# CH641 register map
Vendor: WCH Ltd.; File version: 1.1
Registers are 32-bit, read-write, reset 0x0 unless marked. A register's access mark holds for its fields unless they carry their own. Offsets are from the block's base; [hi:lo] are bit positions; {n}, {i} and the like mark numbered series.

## PFIC — Programmable Fast Interrupt Controller
Base 0xE000E000
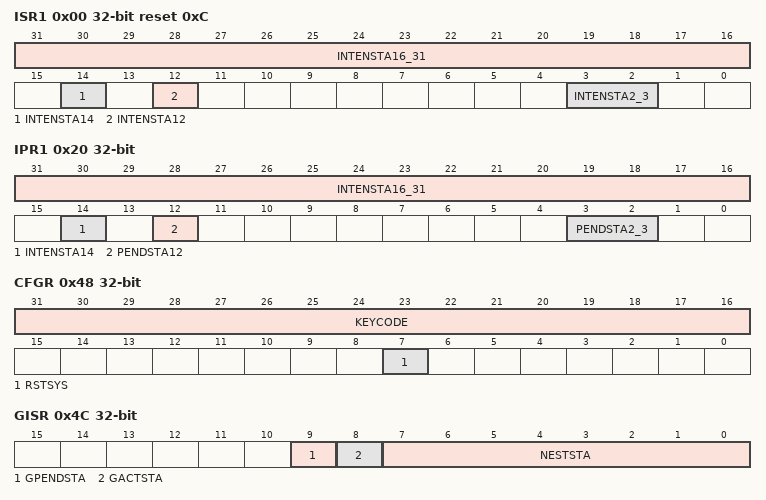
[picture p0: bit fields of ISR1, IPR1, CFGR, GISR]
0x00 ISR1 ro reset 0xC — Interrupt Status Register
  [31:16] INTENSTA16_31 — Interrupt ID Status
  [14] INTENSTA14 — Interrupt ID Status
  [12] INTENSTA12 — Interrupt ID Status
  [3:2] INTENSTA2_3 — Interrupt ID Status
0x04 ISR2 ro — Interrupt Status Register
  [6:0] INTENSTA — Interrupt ID Status
0x20 IPR1 ro — Interrupt Pending Register
  [31:16] INTENSTA16_31 — PENDSTA
  [14] INTENSTA14 — PENDSTA
  [12] PENDSTA12 — PENDSTA
  [3:2] PENDSTA2_3 — PENDSTA
0x24 IPR2 ro — Interrupt Pending Register
  [6:0] PENDSTA32_38 — PENDSTA
0x40 ITHRESDR — Interrupt Priority Register
  [7:0] THRESHOLD
0x48 CFGR wo — Interrupt Config Register
  [31:16] KEYCODE
  [7] RSTSYS — RESET System
0x4C GISR ro — Interrupt Global Register
  [9] GPENDSTA, [8] GACTSTA, [7:0] NESTSTA
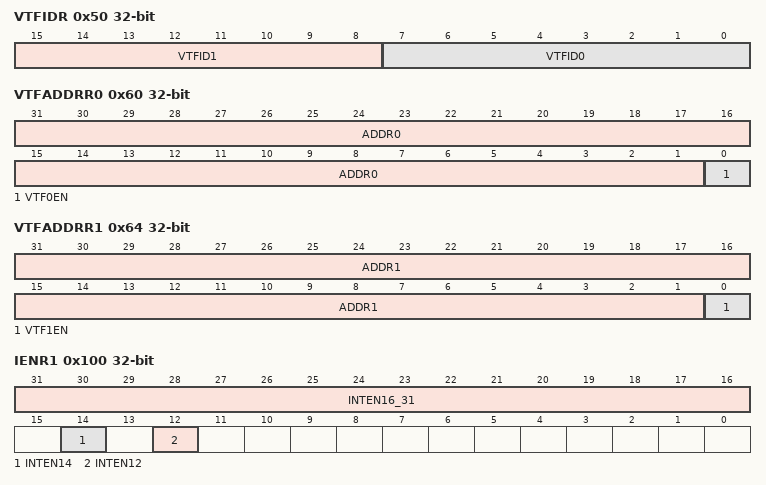
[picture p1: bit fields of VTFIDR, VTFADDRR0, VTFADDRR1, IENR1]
0x50 VTFIDR — ID Config Register
  [15:8] VTFID1, [7:0] VTFID0
0x60 VTFADDRR0 — Interrupt 0 address Register
  [31:1] ADDR0, [0] VTF0EN
0x64 VTFADDRR1 — Interrupt 1 address Register
  [31:1] ADDR1, [0] VTF1EN
0x100 IENR1 wo — Interrupt Setting Register
  [31:16] INTEN16_31, [14] INTEN14, [12] INTEN12
0x104 IENR2 wo — Interrupt Setting Register
  [6:0] INTEN — INTEN32_38
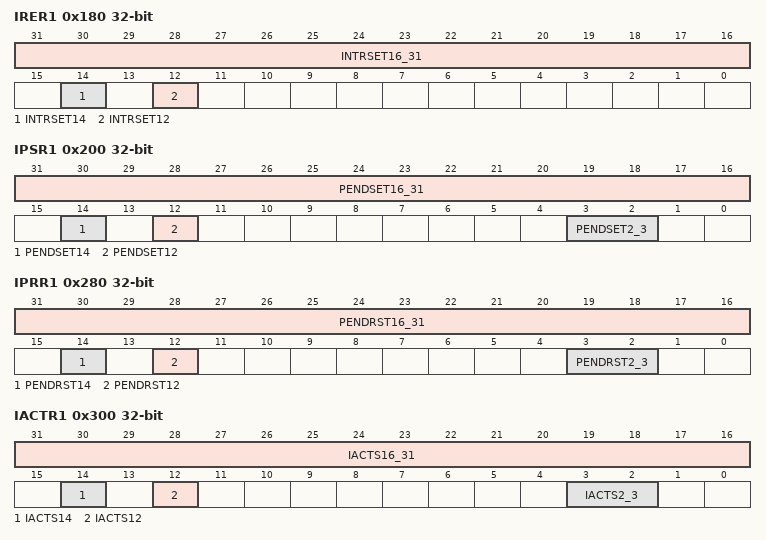
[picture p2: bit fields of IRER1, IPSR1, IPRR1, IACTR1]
0x180 IRER1 wo — Interrupt Clear Register
  [31:16] INTRSET16_31, [14] INTRSET14, [12] INTRSET12
0x184 IRER2 wo — Interrupt Clear Register
  [6:0] INTRSET38_32
0x200 IPSR1 wo — Interrupt Pending Register
  [31:16] PENDSET16_31 — PENDSET
  [14] PENDSET14 — PENDSET
  [12] PENDSET12 — PENDSET
  [3:2] PENDSET2_3 — PENDSET
0x204 IPSR2 wo — Interrupt Pending Register
  [6:0] PENDSET32_38
0x280 IPRR1 wo — Interrupt Pending Clear Register
  [31:16] PENDRST16_31 — PENDRESET
  [14] PENDRST14 — PENDRESET
  [12] PENDRST12 — PENDRESET
  [3:2] PENDRST2_3 — PENDRESET
0x284 IPRR2 wo — Interrupt Pending Clear Register
  [6:0] PENDRST32_38 — PENDRESET32_38
0x300 IACTR1 wo — Interrupt ACTIVE Register
  [31:16] IACTS16_31 — IACTS
  [14] IACTS14 — IACTS
  [12] IACTS12 — IACTS
  [3:2] IACTS2_3 — IACTS
0x304 IACTR2 wo — Interrupt ACTIVE Register
  [6:0] IACTS
{0x400+i} IPRIOR{i} 8-bit (i=0..63) — Interrupt Priority Register
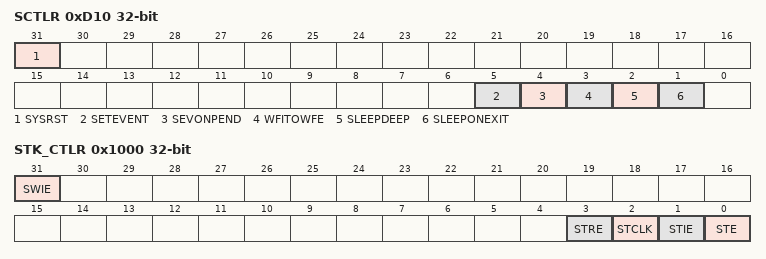
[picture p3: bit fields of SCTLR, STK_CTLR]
0xD10 SCTLR — System Control Register
  [31] SYSRST — SYSRESET
  [5] SETEVENT
  [4] SEVONPEND
  [3] WFITOWFE
  [2] SLEEPDEEP
  [1] SLEEPONEXIT
0x1000 STK_CTLR — System counter control register
  [31] SWIE — System software triggered interrupts enable
  [3] STRE — System reload register
  [2] STCLK — System selects the clock source
  [1] STIE — System counter interrupt enable
  [0] STE — System counter enable
0x1004 STK_SR — System START
  [0] CNTIF
0x1008 STK_CNTL — System counter low register
  [31:0] CNT
0x1010 STK_CMPLR — System compare low register
  [31:0] CMP

## USBPD — USBPD configuration
Base 0x40024000
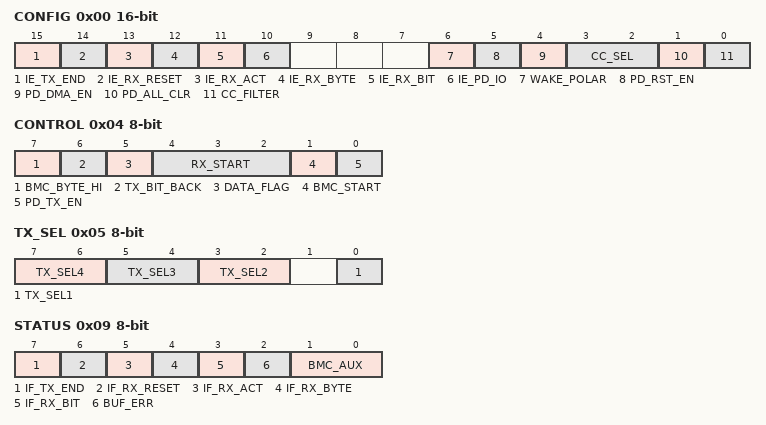
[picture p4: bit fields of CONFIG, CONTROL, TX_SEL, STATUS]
0x00 CONFIG 16-bit — PD interrupt enable register
  [15] IE_TX_END — transfer complete register
  [14] IE_RX_RESET — Receive complete rst register
  [13] IE_RX_ACT — Receive complete register
  [12] IE_RX_BYTE — Receive byte register
  [11] IE_RX_BIT — bit interrupt Enable
  [10] IE_PD_IO — IO Enable
  [6] WAKE_POLAR — wakeup polarity
  [5] PD_RST_EN — PD RST Enable
  [4] PD_DMA_EN — PD DMA Enable
  [3:2] CC_SEL — PD Commutation port
  [1] PD_ALL_CLR — PD ITClear
  [0] CC_FILTER — PIN filtering enabled
0x02 BMC_CLK_CNT 16-bit — BMC sampling clock counter
  [8:0] BMC_CLK_CNT — R/T counter
0x04 CONTROL 8-bit access per field — PD Send and receive enable register
  [7] BMC_BYTE_HI ro — BMC_BYTE_HI value
  [6] TX_BIT_BACK ro — TX_BIT_BACK value
  [5] DATA_FLAG ro — DATA_FLAG value
  [4:2] RX_START ro — PD receive status identification
  [1] BMC_START rw — BMC_START value
  [0] PD_TX_EN rw — PD_TX_EN value
0x05 TX_SEL 8-bit — SOP port selection register
  [7:6] TX_SEL4 — K-CODE4 type selection
  [5:4] TX_SEL3 — K-CODE3 type selection
  [3:2] TX_SEL2 — K-CODE2 type selection
  [0] TX_SEL1 — K-CODE1 type selection
0x06 BMC_TX_SZ 16-bit — PD send length register
  [8:0] BMC_TX_SZ — BMC_TX_SZ value
0x08 DATA_BUF 8-bit ro — DMA cache data register
  [7:0] DATA_BUF — DATA_BUF value
0x09 STATUS 8-bit access per field — PD interrupt flag register
  [7] IF_TX_END rw — IF_TX_END value
  [6] IF_RX_RESET rw — IF_RX_RESET value
  [5] IF_RX_ACT rw — IF_RX_ACT value
  [4] IF_RX_BYTE rw — IF_RX_BYTE value
  [3] IF_RX_BIT rw — IF_RX_BIT value
  [2] BUF_ERR rw — BUF_ERR value
  [1:0] BMC_AUX ro — BMC_AUX value
0x0A BMC_BYTE_CNT 16-bit ro — Byte counter
  [8:0] BMC_BYTE_CNT — BMC_BYTE_CNT value
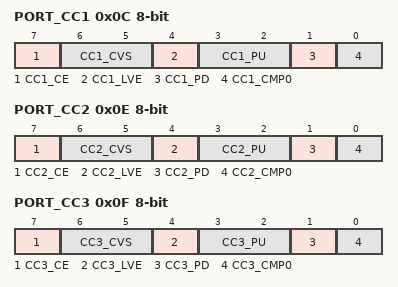
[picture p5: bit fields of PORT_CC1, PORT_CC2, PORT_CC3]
0x0C PORT_CC1 8-bit access per field — CC1 port control register
  [7] CC1_CE rw — CC1 voltage comparator enable
  [6:5] CC1_CVS rw — CC1 voltage comparator reference voltage
  [4] CC1_LVE rw — CC1 port output of the low voltage
  [3:2] CC1_PU rw — CC1 port pull-up current selection
  [1] CC1_PD rw — CC1 port pull-down resistor enable
  [0] CC1_CMP0 ro — CC1 output of the voltage comparator
0x0E PORT_CC2 8-bit access per field — CC2 port control register
  [7] CC2_CE rw — CC2 voltage comparator enable
  [6:5] CC2_CVS rw — CC2 voltage comparator reference voltage
  [4] CC2_LVE rw — CC2 port output of the low voltage
  [3:2] CC2_PU rw — CC2 port pull-up current selection
  [1] CC2_PD rw — CC2 port pull-down resistor enable
  [0] CC2_CMP0 ro — CC2 output of the voltage comparator
0x0F PORT_CC3 8-bit access per field — CC3 port control register
  [7] CC3_CE rw — CC3 voltage comparator enable
  [6:5] CC3_CVS rw — CC3 voltage comparator reference voltage
  [4] CC3_LVE rw — CC3 port output of the low voltage
  [3:2] CC3_PU rw — CC3 port pull-up current selection
  [1] CC3_PD rw — CC3 port pull-down resistor enable
  [0] CC3_CMP0 ro — CC3 output of the voltage comparator
0x10 DMA 16-bit — PD buffer start address register
  [11:0] USBPD_DMA_ADDR — USBPD_DMA_ADDR value
